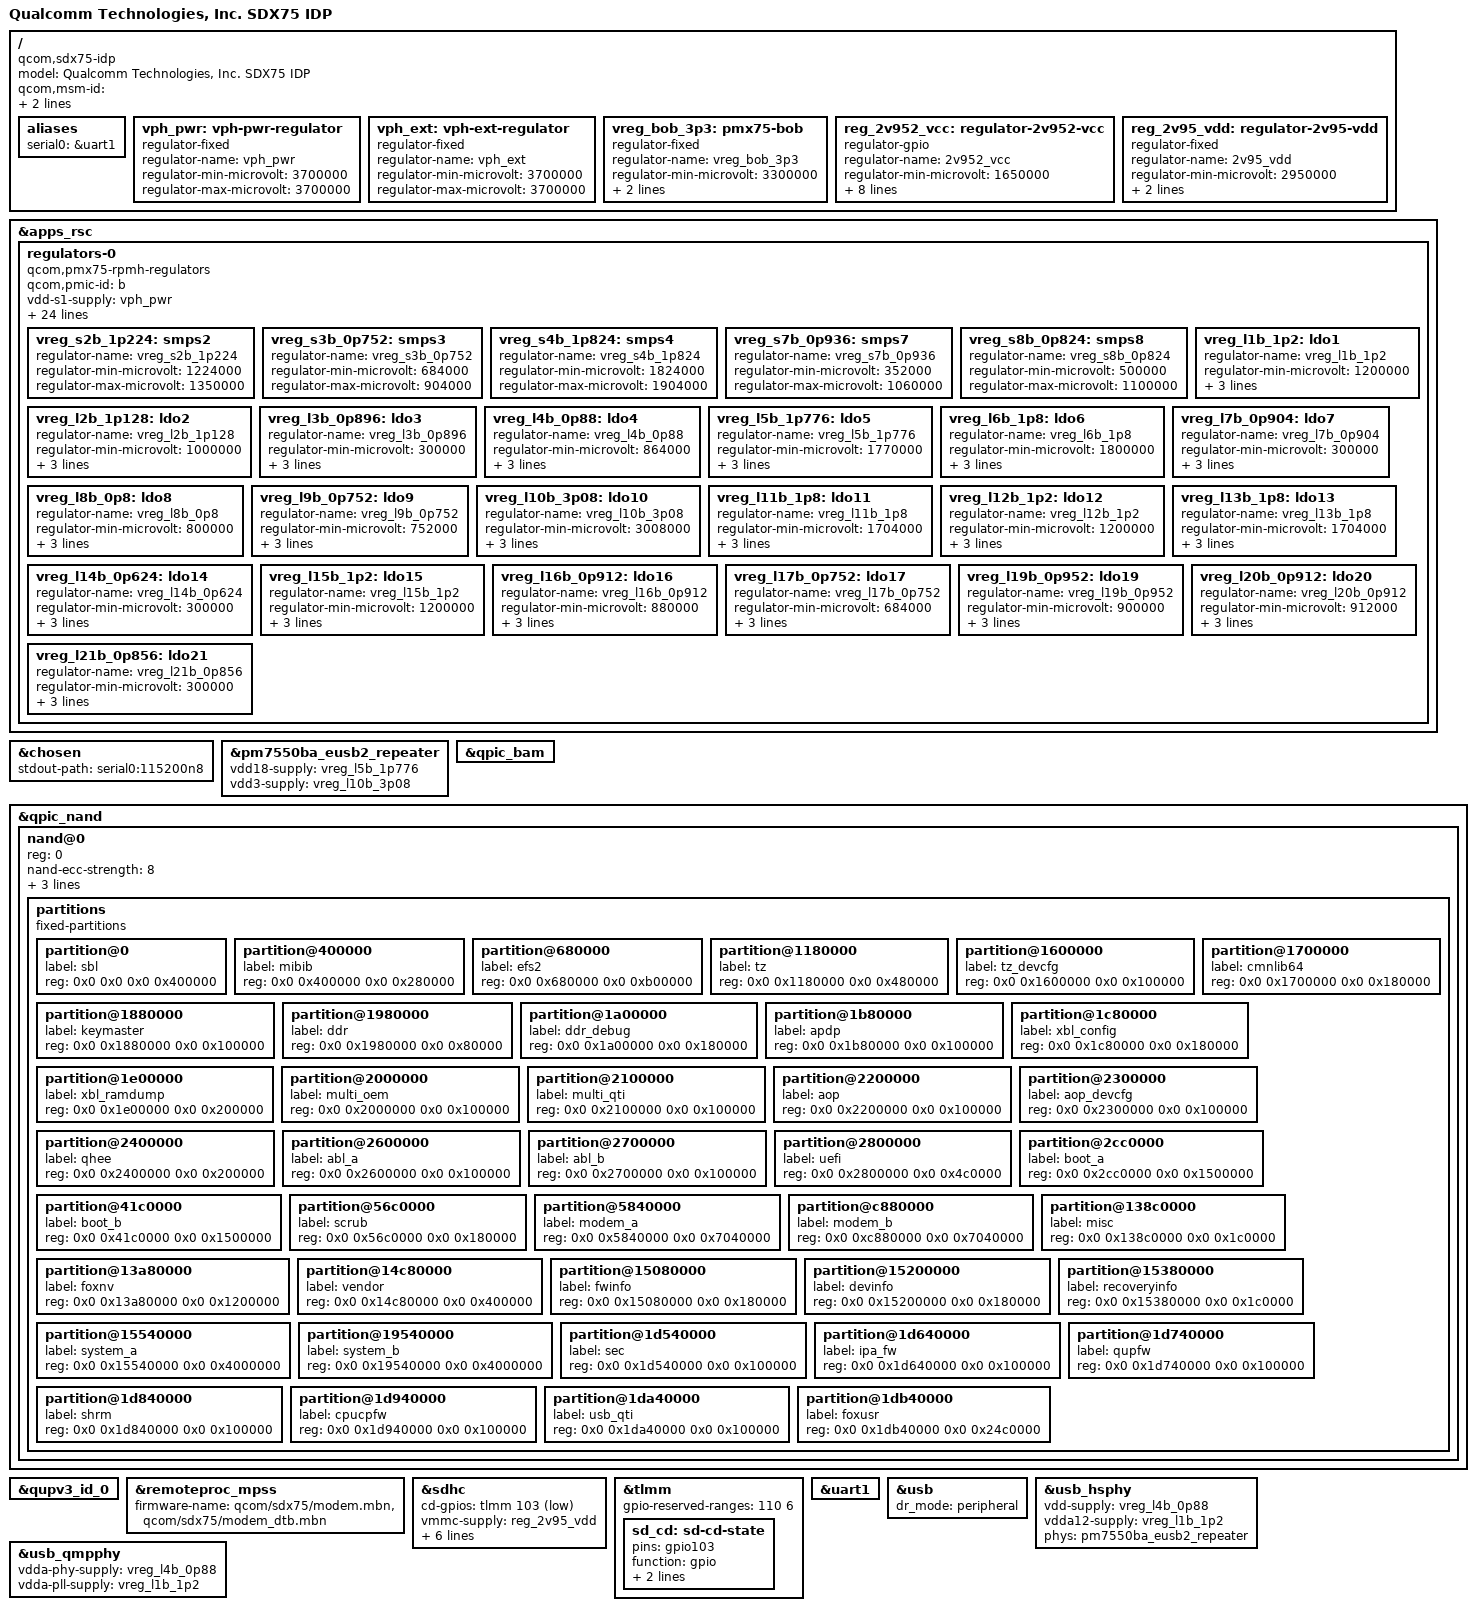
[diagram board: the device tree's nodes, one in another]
// SPDX-License-Identifier: BSD-3-Clause
/*
 * Copyright (c) 2023 Qualcomm Innovation Center, Inc. All rights reserved.
 */

/dts-v1/;

#include <dt-bindings/regulator/qcom,rpmh-regulator.h>
#include "sdx75.dtsi"
#include "pm7550ba.dtsi"
#include "pmk8550.dtsi"
#include "pmx75.dtsi"

/ {
	model = "Qualcomm Technologies, Inc. SDX75 IDP";
	compatible = "qcom,sdx75-idp", "qcom,sdx75";

	qcom,msm-id = <0x244 0x10000 0x262 0x10000 0x22c 0x10000 0x261 0x10000>;
	qcom,board-id = <0x4040022 0x204>;

	aliases {
		serial0 = &uart1;
	};

	vph_pwr: vph-pwr-regulator {
		compatible = "regulator-fixed";
		regulator-name = "vph_pwr";
		regulator-min-microvolt = <3700000>;
		regulator-max-microvolt = <3700000>;
	};

	vph_ext: vph-ext-regulator {
		compatible = "regulator-fixed";
		regulator-name = "vph_ext";
		regulator-min-microvolt = <3700000>;
		regulator-max-microvolt = <3700000>;
	};

	vreg_bob_3p3: pmx75-bob {
		compatible = "regulator-fixed";
		regulator-name = "vreg_bob_3p3";
		regulator-min-microvolt = <3300000>;
		regulator-max-microvolt = <3300000>;

		vin-supply = <&vph_ext>;
	};

	reg_2v952_vcc: regulator-2v952-vcc {
		compatible = "regulator-gpio";
		regulator-name = "2v952_vcc";
		regulator-min-microvolt = <1650000>;
		regulator-max-microvolt = <3600000>;
		enable-gpios = <&tlmm 102 GPIO_ACTIVE_HIGH>;
		gpios = <&tlmm 84 GPIO_ACTIVE_HIGH>;
		states = <1650000 0>, <3600000 1>;
		startup-delay-us = <5000>;
		enable-active-high;
		regulator-boot-on;

		vin-supply = <&vph_ext>;
	};

	reg_2v95_vdd: regulator-2v95-vdd {
		compatible = "regulator-fixed";
		regulator-name = "2v95_vdd";
		regulator-min-microvolt = <2950000>;
		regulator-max-microvolt = <2950000>;
		vin-supply = <&reg_2v952_vcc>;
	};
};

&apps_rsc {
	regulators-0 {
		compatible = "qcom,pmx75-rpmh-regulators";
		qcom,pmic-id = "b";

		vdd-s1-supply = <&vph_pwr>;
		vdd-s2-supply = <&vph_pwr>;
		vdd-s3-supply = <&vph_pwr>;
		vdd-s4-supply = <&vph_pwr>;
		vdd-s5-supply = <&vph_pwr>;
		vdd-s6-supply = <&vph_pwr>;
		vdd-s7-supply = <&vph_pwr>;
		vdd-s8-supply = <&vph_pwr>;
		vdd-s9-supply = <&vph_pwr>;
		vdd-s10-supply = <&vph_pwr>;
		vdd-l1-supply = <&vreg_s2b_1p224>;
		vdd-l2-l18-supply = <&vreg_s2b_1p224>;
		vdd-l3-supply = <&vreg_s7b_0p936>;
		vdd-l4-l16-supply = <&vreg_s7b_0p936>;
		vdd-l5-l6-supply = <&vreg_s4b_1p824>;
		vdd-l7-supply = <&vreg_s7b_0p936>;
		vdd-l8-l9-supply = <&vreg_s8b_0p824>;
		vdd-l10-supply = <&vreg_bob_3p3>;
		vdd-l11-l13-supply = <&vreg_bob_3p3>;
		vdd-l12-supply = <&vreg_s2b_1p224>;
		vdd-l14-supply = <&vreg_s3b_0p752>;
		vdd-l15-supply = <&vreg_s2b_1p224>;
		vdd-l17-supply = <&vreg_s8b_0p824>;
		vdd-l19-supply = <&vreg_s7b_0p936>;
		vdd-l20-l21-supply = <&vreg_s7b_0p936>;

		vreg_s2b_1p224: smps2 {
			regulator-name = "vreg_s2b_1p224";
			regulator-min-microvolt = <1224000>;
			regulator-max-microvolt = <1350000>;
		};

		vreg_s3b_0p752: smps3 {
			regulator-name = "vreg_s3b_0p752";
			regulator-min-microvolt = <684000>;
			regulator-max-microvolt = <904000>;
		};

		vreg_s4b_1p824: smps4 {
			regulator-name = "vreg_s4b_1p824";
			regulator-min-microvolt = <1824000>;
			regulator-max-microvolt = <1904000>;
		};

		vreg_s7b_0p936: smps7 {
			regulator-name = "vreg_s7b_0p936";
			regulator-min-microvolt = <352000>;
			regulator-max-microvolt = <1060000>;
		};

		vreg_s8b_0p824: smps8 {
			regulator-name = "vreg_s8b_0p824";
			regulator-min-microvolt = <500000>;
			regulator-max-microvolt = <1100000>;
		};

		vreg_l1b_1p2: ldo1 {
			regulator-name = "vreg_l1b_1p2";
			regulator-min-microvolt = <1200000>;
			regulator-max-microvolt = <1200000>;
			regulator-initial-mode = <RPMH_REGULATOR_MODE_HPM>;
		};

		vreg_l2b_1p128: ldo2 {
			regulator-name = "vreg_l2b_1p128";
			regulator-min-microvolt = <1000000>;
			regulator-max-microvolt = <1160000>;
			regulator-initial-mode = <RPMH_REGULATOR_MODE_HPM>;
		};

		vreg_l3b_0p896: ldo3 {
			regulator-name = "vreg_l3b_0p896";
			regulator-min-microvolt = <300000>;
			regulator-max-microvolt = <1040000>;
			regulator-initial-mode = <RPMH_REGULATOR_MODE_HPM>;
		};

		vreg_l4b_0p88: ldo4 {
			regulator-name = "vreg_l4b_0p88";
			regulator-min-microvolt = <864000>;
			regulator-max-microvolt = <912000>;
			regulator-initial-mode = <RPMH_REGULATOR_MODE_HPM>;
		};

		vreg_l5b_1p776: ldo5 {
			regulator-name = "vreg_l5b_1p776";
			regulator-min-microvolt = <1770000>;
			regulator-max-microvolt = <1800000>;
			regulator-initial-mode = <RPMH_REGULATOR_MODE_HPM>;
		};

		vreg_l6b_1p8: ldo6 {
			regulator-name = "vreg_l6b_1p8";
			regulator-min-microvolt = <1800000>;
			regulator-max-microvolt = <1800000>;
			regulator-initial-mode = <RPMH_REGULATOR_MODE_HPM>;
		};

		vreg_l7b_0p904: ldo7 {
			regulator-name = "vreg_l7b_0p904";
			regulator-min-microvolt = <300000>;
			regulator-max-microvolt = <960000>;
			regulator-initial-mode = <RPMH_REGULATOR_MODE_HPM>;
		};

		vreg_l8b_0p8: ldo8 {
			regulator-name = "vreg_l8b_0p8";
			regulator-min-microvolt = <800000>;
			regulator-max-microvolt = <800000>;
			regulator-initial-mode = <RPMH_REGULATOR_MODE_HPM>;
		};

		vreg_l9b_0p752: ldo9 {
			regulator-name = "vreg_l9b_0p752";
			regulator-min-microvolt = <752000>;
			regulator-max-microvolt = <800000>;
			regulator-initial-mode = <RPMH_REGULATOR_MODE_HPM>;
		};

		vreg_l10b_3p08: ldo10 {
			regulator-name = "vreg_l10b_3p08";
			regulator-min-microvolt = <3008000>;
			regulator-max-microvolt = <3088000>;
			regulator-initial-mode = <RPMH_REGULATOR_MODE_HPM>;
		};

		vreg_l11b_1p8: ldo11 {
			regulator-name = "vreg_l11b_1p8";
			regulator-min-microvolt = <1704000>;
			regulator-max-microvolt = <2928000>;
			regulator-initial-mode = <RPMH_REGULATOR_MODE_HPM>;
		};

		vreg_l12b_1p2: ldo12 {
			regulator-name = "vreg_l12b_1p2";
			regulator-min-microvolt = <1200000>;
			regulator-max-microvolt = <1200000>;
			regulator-initial-mode = <RPMH_REGULATOR_MODE_HPM>;
		};

		vreg_l13b_1p8: ldo13 {
			regulator-name = "vreg_l13b_1p8";
			regulator-min-microvolt = <1704000>;
			regulator-max-microvolt = <2928000>;
			regulator-initial-mode = <RPMH_REGULATOR_MODE_HPM>;
		};

		vreg_l14b_0p624: ldo14 {
			regulator-name = "vreg_l14b_0p624";
			regulator-min-microvolt = <300000>;
			regulator-max-microvolt = <800000>;
			regulator-initial-mode = <RPMH_REGULATOR_MODE_HPM>;
		};

		vreg_l15b_1p2: ldo15 {
			regulator-name = "vreg_l15b_1p2";
			regulator-min-microvolt = <1200000>;
			regulator-max-microvolt = <1200000>;
			regulator-initial-mode = <RPMH_REGULATOR_MODE_HPM>;
		};

		vreg_l16b_0p912: ldo16 {
			regulator-name = "vreg_l16b_0p912";
			regulator-min-microvolt = <880000>;
			regulator-max-microvolt = <920000>;
			regulator-initial-mode = <RPMH_REGULATOR_MODE_HPM>;
		};

		vreg_l17b_0p752: ldo17 {
			regulator-name = "vreg_l17b_0p752";
			regulator-min-microvolt = <684000>;
			regulator-max-microvolt = <957600>;
			regulator-initial-mode = <RPMH_REGULATOR_MODE_HPM>;
		};

		vreg_l19b_0p952: ldo19 {
			regulator-name = "vreg_l19b_0p952";
			regulator-min-microvolt = <900000>;
			regulator-max-microvolt = <960000>;
			regulator-initial-mode = <RPMH_REGULATOR_MODE_HPM>;
		};

		vreg_l20b_0p912: ldo20 {
			regulator-name = "vreg_l20b_0p912";
			regulator-min-microvolt = <912000>;
			regulator-max-microvolt = <952000>;
			regulator-initial-mode = <RPMH_REGULATOR_MODE_HPM>;
		};

		vreg_l21b_0p856: ldo21 {
			regulator-name = "vreg_l21b_0p856";
			regulator-min-microvolt = <300000>;
			regulator-max-microvolt = <1000000>;
			regulator-initial-mode = <RPMH_REGULATOR_MODE_HPM>;
		};
	};
};

&chosen {
	stdout-path = "serial0:115200n8";
};

&pm7550ba_eusb2_repeater {
	vdd18-supply = <&vreg_l5b_1p776>;
	vdd3-supply = <&vreg_l10b_3p08>;
};

&qpic_bam {
	status = "okay";
};

&qpic_nand {
	status = "okay";

	nand@0 {
		reg = <0>;

		nand-ecc-strength = <8>;
		nand-ecc-step-size = <512>;
		nand-bus-width = <8>;
		/* efs2 partition is secured */
		secure-regions = /bits/ 64 <0x680000 0xb00000>;

		partitions {
			compatible = "fixed-partitions";
			#address-cells = <2>;
			#size-cells = <2>;

			partition@0 {
				label = "sbl";
				reg = <0x0 0x0 0x0 0x400000>;
			};

			partition@400000 {
				label = "mibib";
				reg = <0x0 0x400000 0x0 0x280000>;
			};

			partition@680000 {
				label = "efs2";
				reg = <0x0 0x680000 0x0 0xb00000>;
			};

			partition@1180000 {
				label = "tz";
				reg = <0x0 0x1180000 0x0 0x480000>;
			};

			partition@1600000 {
				label = "tz_devcfg";
				reg = <0x0 0x1600000 0x0 0x100000>;
			};

			partition@1700000 {
				label = "cmnlib64";
				reg = <0x0 0x1700000 0x0 0x180000>;
			};

			partition@1880000 {
				label = "keymaster";
				reg = <0x0 0x1880000 0x0 0x100000>;
			};

			partition@1980000 {
				label = "ddr";
				reg = <0x0 0x1980000 0x0 0x80000>;
			};

			partition@1a00000 {
				label = "ddr_debug";
				reg = <0x0 0x1a00000 0x0 0x180000>;
			};

			partition@1b80000 {
				label = "apdp";
				reg = <0x0 0x1b80000 0x0 0x100000>;
			};

			partition@1c80000 {
				label = "xbl_config";
				reg = <0x0 0x1c80000 0x0 0x180000>;
			};

			partition@1e00000 {
				label = "xbl_ramdump";
				reg = <0x0 0x1e00000 0x0 0x200000>;
			};

			partition@2000000 {
				label = "multi_oem";
				reg = <0x0 0x2000000 0x0 0x100000>;
			};

			partition@2100000 {
				label = "multi_qti";
				reg = <0x0 0x2100000 0x0 0x100000>;
			};

			partition@2200000 {
				label = "aop";
				reg = <0x0 0x2200000 0x0 0x100000>;
			};

			partition@2300000 {
				label = "aop_devcfg";
				reg = <0x0 0x2300000 0x0 0x100000>;
			};

			partition@2400000 {
				label = "qhee";
				reg = <0x0 0x2400000 0x0 0x200000>;
			};

			partition@2600000 {
				label = "abl_a";
				reg = <0x0 0x2600000 0x0 0x100000>;
			};

			partition@2700000 {
				label = "abl_b";
				reg = <0x0 0x2700000 0x0 0x100000>;
			};

			partition@2800000 {
				label = "uefi";
				reg = <0x0 0x2800000 0x0 0x4c0000>;
			};

			partition@2cc0000 {
				label = "boot_a";
				reg = <0x0 0x2cc0000 0x0 0x1500000>;
			};

			partition@41c0000 {
				label = "boot_b";
				reg = <0x0 0x41c0000 0x0 0x1500000>;
			};

			partition@56c0000 {
				label = "scrub";
				reg = <0x0 0x56c0000 0x0 0x180000>;
			};

			partition@5840000 {
				label = "modem_a";
				reg = <0x0 0x5840000 0x0 0x7040000>;
			};

			partition@c880000 {
				label = "modem_b";
				reg = <0x0 0xc880000 0x0 0x7040000>;
			};

			partition@138c0000 {
				label = "misc";
				reg = <0x0 0x138c0000 0x0 0x1c0000>;
			};

			partition@13a80000 {
				label = "foxnv";
				reg = <0x0 0x13a80000 0x0 0x1200000>;
			};

			partition@14c80000 {
				label = "vendor";
				reg = <0x0 0x14c80000 0x0 0x400000>;
			};

			partition@15080000 {
				label = "fwinfo";
				reg = <0x0 0x15080000 0x0 0x180000>;
			};

			partition@15200000 {
				label = "devinfo";
				reg = <0x0 0x15200000 0x0 0x180000>;
			};

			partition@15380000 {
				label = "recoveryinfo";
				reg = <0x0 0x15380000 0x0 0x1c0000>;
			};

			partition@15540000 {
				label = "system_a";
				reg = <0x0 0x15540000 0x0 0x4000000>;
			};

			partition@19540000 {
				label = "system_b";
				reg = <0x0 0x19540000 0x0 0x4000000>;
			};

			partition@1d540000 {
				label = "sec";
				reg = <0x0 0x1d540000 0x0 0x100000>;
			};

			partition@1d640000 {
				label = "ipa_fw";
				reg = <0x0 0x1d640000 0x0 0x100000>;
			};

			partition@1d740000 {
				label = "qupfw";
				reg = <0x0 0x1d740000 0x0 0x100000>;
			};

			partition@1d840000 {
				label = "shrm";
				reg = <0x0 0x1d840000 0x0 0x100000>;
			};

			partition@1d940000 {
				label = "cpucpfw";
				reg = <0x0 0x1d940000 0x0 0x100000>;
			};

			partition@1da40000 {
				label = "usb_qti";
				reg = <0x0 0x1da40000 0x0 0x100000>;
			};

			partition@1db40000 {
				label = "foxusr";
				reg = <0x0 0x1db40000 0x0 0x24c0000>;
			};
		};
	};
};

&qupv3_id_0 {
	status = "okay";
};

&remoteproc_mpss {
	firmware-name = "qcom/sdx75/modem.mbn",
			"qcom/sdx75/modem_dtb.mbn";
	status = "okay";
};

&sdhc {
	cd-gpios = <&tlmm 103 GPIO_ACTIVE_LOW>;
	vmmc-supply = <&reg_2v95_vdd>;
	vqmmc-supply = <&reg_2v952_vcc>;
	bus-width = <4>;
	no-sdio;
	no-mmc;

	pinctrl-0 = <&sdc1_default &sd_cd>;
	pinctrl-1 = <&sdc1_sleep &sd_cd>;
	pinctrl-names = "default", "sleep";

	status = "okay";
};

&tlmm {
	gpio-reserved-ranges = <110 6>;

	sd_cd: sd-cd-state {
		pins = "gpio103";
		function = "gpio";
		drive-strength = <2>;
		bias-pull-up;
	};
};

&uart1 {
	status = "okay";
};

&usb {
	dr_mode = "peripheral";

	status = "okay";
};

&usb_hsphy {
	vdd-supply = <&vreg_l4b_0p88>;
	vdda12-supply = <&vreg_l1b_1p2>;

	phys = <&pm7550ba_eusb2_repeater>;

	status = "okay";
};

&usb_qmpphy {
	vdda-phy-supply = <&vreg_l4b_0p88>;
	vdda-pll-supply = <&vreg_l1b_1p2>;

	status = "okay";
};
